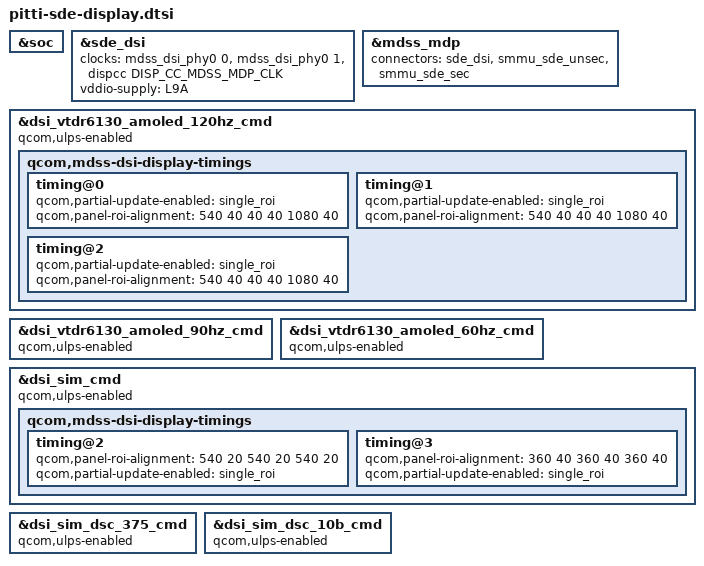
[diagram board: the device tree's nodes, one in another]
#include <dt-bindings/clock/qcom,dispcc-pitti.h>
#include "pitti-sde-display-common.dtsi"

&soc {
};

&sde_dsi {
	clocks = <&mdss_dsi_phy0 0>,
		 <&mdss_dsi_phy0 1>,
		 /*
		  * Currently the dsi clock handles are under the dsi
		  * controller DT node. As soon as the controller probe
		  * finishes, the dispcc sync state can get called before
		  * the dsi_display probe potentially disturbing the clock
		  * votes for cont_splash use case. Hence we are no longer
		  * protected by the component model in this case against the
		  * disp cc sync state getting triggered after the dsi_ctrl
		  * probe. To protect against this incorrect sync state trigger
		  * add this dummy MDP clk vote handle to the dsi_display
		  * DT node. Since the dsi_display driver does not parse
		  * MDP clock nodes, no actual vote shall be added and this
		  * change is done just to satisfy sync state requirements.
		  */
		 <&dispcc DISP_CC_MDSS_MDP_CLK>;
	clock-names = "pll_byte_clk0", "pll_dsi_clk0",
		      "mdp_core_clk";

	vddio-supply = <&L9A>;
};

&mdss_mdp {
	connectors = <&sde_dsi &smmu_sde_unsec &smmu_sde_sec>;
};

&dsi_vtdr6130_amoled_120hz_cmd {
	qcom,ulps-enabled;
	qcom,mdss-dsi-display-timings {
		timing@0 {
			qcom,partial-update-enabled = "single_roi";
			qcom,panel-roi-alignment = <540 40 40 40 1080 40>;
		};

		timing@1 {
			qcom,partial-update-enabled = "single_roi";
			qcom,panel-roi-alignment = <540 40 40 40 1080 40>;
		};

		timing@2 {
			qcom,partial-update-enabled = "single_roi";
			qcom,panel-roi-alignment = <540 40 40 40 1080 40>;
		};
	};
};

&dsi_vtdr6130_amoled_90hz_cmd {
	qcom,ulps-enabled;
};

&dsi_vtdr6130_amoled_60hz_cmd {
	qcom,ulps-enabled;
};

&dsi_sim_cmd {
	qcom,ulps-enabled;
	qcom,mdss-dsi-display-timings {
		timing@2 { /* FHD 60FPS cmd mode*/
			qcom,panel-roi-alignment = <540 20 540 20 540 20>;
			qcom,partial-update-enabled = "single_roi";
		};

		timing@3 { /* HD 60FPS cmd mode*/
			qcom,panel-roi-alignment = <360 40 360 40 360 40>;
			qcom,partial-update-enabled = "single_roi";
		};
	};
};

&dsi_sim_dsc_375_cmd {
	qcom,ulps-enabled;
};

&dsi_sim_dsc_10b_cmd {
	qcom,ulps-enabled;
};
